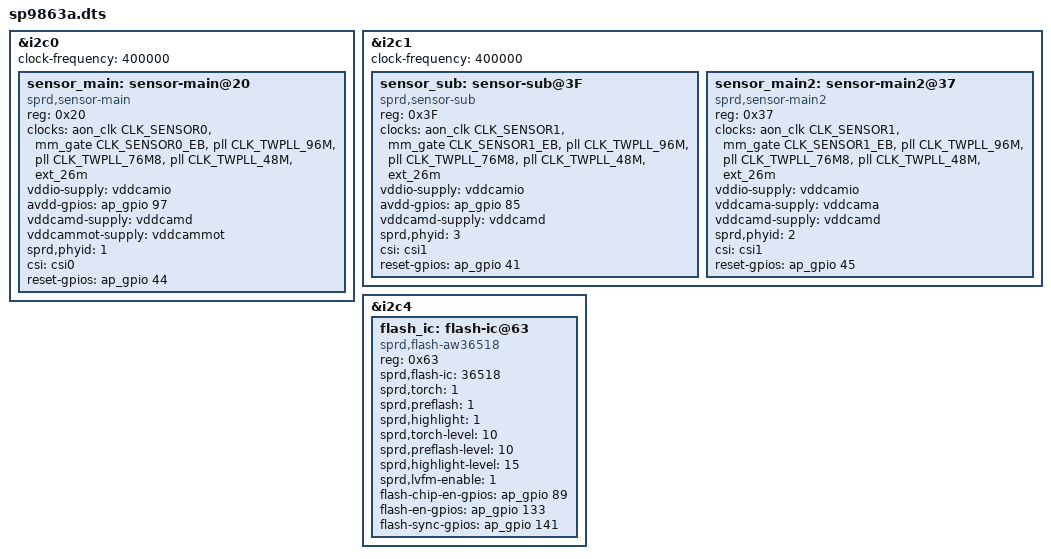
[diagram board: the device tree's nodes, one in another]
/*****************************************
Do not modify dts file, please modify according dtsi file
******************************************/
#include "../sp9863a.dts"
#include "sprd_base_diff.dtsi"

&i2c0 {
	status = "okay";
	clock-frequency = <400000>;

	sensor_main: sensor-main@20 {
		compatible = "sprd,sensor-main";
		reg = <0x20>;
		clock-names = "clk_src","sensor_eb",
			"clk_96m","clk_76m8",
			"clk_48m","clk_26m";
		clocks = <&aon_clk CLK_SENSOR0>, <&mm_gate CLK_SENSOR0_EB>,
			<&pll CLK_TWPLL_96M>,<&pll CLK_TWPLL_76M8>,
			<&pll CLK_TWPLL_48M>,<&ext_26m>;
		vddio-supply = <&vddcamio>;
		avdd-gpios=<&ap_gpio 97 0>;
		vddcamd-supply = <&vddcamd>;
		vddcammot-supply = <&vddcammot>;
		sprd,phyid = <1>;
		csi = <&csi0>;
		reset-gpios = <&ap_gpio 44 0>;
		//power-down-gpios = <&ap_gpio 46 0>;
	};
};

&i2c1 {
	status = "okay";
	clock-frequency = <400000>;

	sensor_sub: sensor-sub@3F {
		compatible = "sprd,sensor-sub";
		reg = <0x3F>;
		clock-names = "clk_src","sensor_eb",
			"clk_96m","clk_76m8",
			"clk_48m","clk_26m";
		clocks = <&aon_clk CLK_SENSOR1>, <&mm_gate CLK_SENSOR1_EB>,
			<&pll CLK_TWPLL_96M>,<&pll CLK_TWPLL_76M8>,
			<&pll CLK_TWPLL_48M>,<&ext_26m>;
		vddio-supply = <&vddcamio>;
		avdd-gpios=<&ap_gpio 85 0>;
		vddcamd-supply = <&vddcamd>;
		sprd,phyid = <3>;
		csi = <&csi1>;
		reset-gpios = <&ap_gpio 41 0>;
		//power-down-gpios = <&ap_gpio 40 0>;
	};

	sensor_main2: sensor-main2@37 {
		compatible = "sprd,sensor-main2";
		reg = <0x37>;
		clock-names = "clk_src","sensor_eb",
			"clk_96m","clk_76m8",
			"clk_48m","clk_26m";
		clocks = <&aon_clk CLK_SENSOR1>, <&mm_gate CLK_SENSOR1_EB>,
			<&pll CLK_TWPLL_96M>,<&pll CLK_TWPLL_76M8>,
			<&pll CLK_TWPLL_48M>,<&ext_26m>;
		vddio-supply = <&vddcamio>;
		vddcama-supply = <&vddcama>;
		vddcamd-supply = <&vddcamd>;
		sprd,phyid = <2>;
		csi = <&csi1>;
		reset-gpios = <&ap_gpio 45 0>;
		//power-down-gpios = <&ap_gpio 47 0>;
	};
};

&i2c4 {
	flash_ic: flash-ic@63 {
		compatible = "sprd,flash-aw36518";
		reg = <0x63>;
		sprd,flash-ic = <36518>;
		sprd,torch = <1>;
		sprd,preflash = <1>;
		sprd,highlight = <1>;
		sprd,torch-level = <10>;
		sprd,preflash-level = <10>;
		sprd,highlight-level = <15>;
		sprd,lvfm-enable = <1>;
		flash-chip-en-gpios = <&ap_gpio 89 0>;
		flash-en-gpios = <&ap_gpio 133 0>;
		flash-sync-gpios = <&ap_gpio 141 0>;
	};
};
